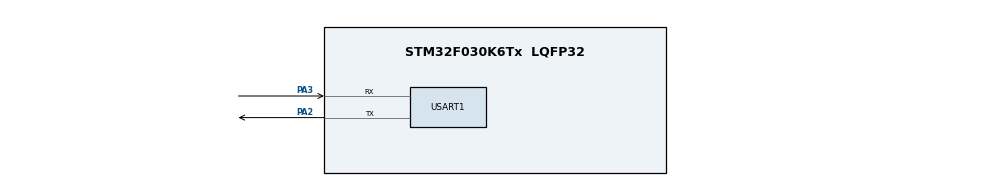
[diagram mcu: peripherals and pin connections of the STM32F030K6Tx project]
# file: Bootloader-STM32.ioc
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Mcu.Family=STM32F0
Mcu.Name=STM32F030K6Tx
Mcu.Package=LQFP32
PA2.Mode=Asynchronous
PA2.Signal=USART1_TX
PA3.Mode=Asynchronous
PA3.Signal=USART1_RX
ProjectManager.HeapSize=0x200
ProjectManager.StackSize=0x400
ProjectManager.TargetToolchain=TrueSTUDIO
USART1.VirtualMode-Asynchronous=VM_ASYNC
board=custom

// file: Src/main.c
/**
  ******************************************************************************
  * @file           : main.c
  * @brief          : Main program body
  ******************************************************************************
  ** This notice applies to any and all portions of this file
  * that are not between comment pairs USER CODE BEGIN and
  * USER CODE END. Other portions of this file, whether
  * inserted by the user or by software development tools
  * are owned by their respective copyright owners.
  *
  * COPYRIGHT(c) 2018 STMicroelectronics
  *
  * Redistribution and use in source and binary forms, with or without modification,
  * are permitted provided that the following conditions are met:
  *   1. Redistributions of source code must retain the above copyright notice,
  *      this list of conditions and the following disclaimer.
  *   2. Redistributions in binary form must reproduce the above copyright notice,
  *      this list of conditions and the following disclaimer in the documentation
  *      and/or other materials provided with the distribution.
  *   3. Neither the name of STMicroelectronics nor the names of its contributors
  *      may be used to endorse or promote products derived from this software
  *      without specific prior written permission.
  *
  * THIS SOFTWARE IS PROVIDED BY THE COPYRIGHT HOLDERS AND CONTRIBUTORS "AS IS"
  * AND ANY EXPRESS OR IMPLIED WARRANTIES, INCLUDING, BUT NOT LIMITED TO, THE
  * IMPLIED WARRANTIES OF MERCHANTABILITY AND FITNESS FOR A PARTICULAR PURPOSE ARE
  * DISCLAIMED. IN NO EVENT SHALL THE COPYRIGHT HOLDER OR CONTRIBUTORS BE LIABLE
  * FOR ANY DIRECT, INDIRECT, INCIDENTAL, SPECIAL, EXEMPLARY, OR CONSEQUENTIAL
  * DAMAGES (INCLUDING, BUT NOT LIMITED TO, PROCUREMENT OF SUBSTITUTE GOODS OR
  * SERVICES; LOSS OF USE, DATA, OR PROFITS; OR BUSINESS INTERRUPTION) HOWEVER
  * CAUSED AND ON ANY THEORY OF LIABILITY, WHETHER IN CONTRACT, STRICT LIABILITY,
  * OR TORT (INCLUDING NEGLIGENCE OR OTHERWISE) ARISING IN ANY WAY OUT OF THE USE
  * OF THIS SOFTWARE, EVEN IF ADVISED OF THE POSSIBILITY OF SUCH DAMAGE.
  *
  ******************************************************************************
  */
#include "main.h"
#include "stm32f0xx_hal.h"

/* USER CODE BEGIN Includes */

#include "boot.h"

/* USER CODE END Includes */

/* USER CODE BEGIN PV */
/* Private variables ---------------------------------------------------------*/

/* USER CODE END PV */

void SystemClock_Config(void);
static void MX_GPIO_Init(void);
static void MX_USART1_UART_Init(void);

/* USER CODE BEGIN PFP */
/* Private function prototypes -----------------------------------------------*/

/* USER CODE END PFP */

int main(void)
{

  /* MCU Configuration----------------------------------------------------------*/

  /* Reset of all peripherals, Initializes the Flash interface and the Systick. */
  HAL_Init();

  /* Configure the system clock */
  SystemClock_Config();

  /* Initialize all configured peripherals */
  MX_GPIO_Init();
  MX_USART1_UART_Init();
  /* USER CODE BEGIN 2 */

  BootInit();

  /* USER CODE END 2 */

  /* Infinite loop */
  /* USER CODE BEGIN WHILE */
  while (1)
  {
	  BootTask();

  /* USER CODE END WHILE */

  }

}

void SystemClock_Config(void)
{

  RCC_OscInitTypeDef RCC_OscInitStruct;
  RCC_ClkInitTypeDef RCC_ClkInitStruct;
  RCC_PeriphCLKInitTypeDef PeriphClkInit;

    /**Initializes the CPU, AHB and APB busses clocks
    */
  RCC_OscInitStruct.OscillatorType = RCC_OSCILLATORTYPE_HSI;
  RCC_OscInitStruct.HSIState = RCC_HSI_ON;
  RCC_OscInitStruct.HSICalibrationValue = 16;
  RCC_OscInitStruct.PLL.PLLState = RCC_PLL_NONE;
  if (HAL_RCC_OscConfig(&RCC_OscInitStruct) != HAL_OK)
  {
    _Error_Handler(__FILE__, __LINE__);
  }

    /**Initializes the CPU, AHB and APB busses clocks
    */
  RCC_ClkInitStruct.ClockType = RCC_CLOCKTYPE_HCLK|RCC_CLOCKTYPE_SYSCLK
                              |RCC_CLOCKTYPE_PCLK1;
  RCC_ClkInitStruct.SYSCLKSource = RCC_SYSCLKSOURCE_HSI;
  RCC_ClkInitStruct.AHBCLKDivider = RCC_SYSCLK_DIV1;
  RCC_ClkInitStruct.APB1CLKDivider = RCC_HCLK_DIV1;

  if (HAL_RCC_ClockConfig(&RCC_ClkInitStruct, FLASH_LATENCY_0) != HAL_OK)
  {
    _Error_Handler(__FILE__, __LINE__);
  }

  PeriphClkInit.PeriphClockSelection = RCC_PERIPHCLK_USART1;
  PeriphClkInit.Usart1ClockSelection = RCC_USART1CLKSOURCE_PCLK1;
  if (HAL_RCCEx_PeriphCLKConfig(&PeriphClkInit) != HAL_OK)
  {
    _Error_Handler(__FILE__, __LINE__);
  }

    /**Configure the Systick interrupt time
    */
  HAL_SYSTICK_Config(HAL_RCC_GetHCLKFreq()/1000);

    /**Configure the Systick
    */
  HAL_SYSTICK_CLKSourceConfig(SYSTICK_CLKSOURCE_HCLK);

  /* SysTick_IRQn interrupt configuration */
  HAL_NVIC_SetPriority(SysTick_IRQn, 0, 0);
}

/* USART1 init function */
static void MX_USART1_UART_Init(void)
{

  LL_USART_InitTypeDef USART_InitStruct;

  LL_GPIO_InitTypeDef GPIO_InitStruct;

  /* Peripheral clock enable */
  LL_APB1_GRP2_EnableClock(LL_APB1_GRP2_PERIPH_USART1);

  /**USART1 GPIO Configuration
  PA2   ------> USART1_TX
  PA3   ------> USART1_RX
  */
  GPIO_InitStruct.Pin = LL_GPIO_PIN_2;
  GPIO_InitStruct.Mode = LL_GPIO_MODE_ALTERNATE;
  GPIO_InitStruct.Speed = LL_GPIO_SPEED_FREQ_HIGH;
  GPIO_InitStruct.OutputType = LL_GPIO_OUTPUT_PUSHPULL;
  GPIO_InitStruct.Pull = LL_GPIO_PULL_NO;
  GPIO_InitStruct.Alternate = LL_GPIO_AF_1;
  LL_GPIO_Init(GPIOA, &GPIO_InitStruct);

  GPIO_InitStruct.Pin = LL_GPIO_PIN_3;
  GPIO_InitStruct.Mode = LL_GPIO_MODE_ALTERNATE;
  GPIO_InitStruct.Speed = LL_GPIO_SPEED_FREQ_HIGH;
  GPIO_InitStruct.OutputType = LL_GPIO_OUTPUT_PUSHPULL;
  GPIO_InitStruct.Pull = LL_GPIO_PULL_NO;
  GPIO_InitStruct.Alternate = LL_GPIO_AF_1;
  LL_GPIO_Init(GPIOA, &GPIO_InitStruct);

  USART_InitStruct.BaudRate = 38400;
  USART_InitStruct.DataWidth = LL_USART_DATAWIDTH_8B;
  USART_InitStruct.StopBits = LL_USART_STOPBITS_1;
  USART_InitStruct.Parity = LL_USART_PARITY_NONE;
  USART_InitStruct.TransferDirection = LL_USART_DIRECTION_TX_RX;
  USART_InitStruct.HardwareFlowControl = LL_USART_HWCONTROL_NONE;
  USART_InitStruct.OverSampling = LL_USART_OVERSAMPLING_16;
  LL_USART_Init(USART1, &USART_InitStruct);

  LL_USART_DisableIT_CTS(USART1);

  LL_USART_DisableOverrunDetect(USART1);

  LL_USART_ConfigAsyncMode(USART1);

  LL_USART_Enable(USART1);

}

/** Pinout Configuration
*/
static void MX_GPIO_Init(void)
{

  /* GPIO Ports Clock Enable */
  LL_AHB1_GRP1_EnableClock(LL_AHB1_GRP1_PERIPH_GPIOA);

}

void _Error_Handler(char *file, int line)
{
  while(1)
  {
  }
}

/************************ (C) COPYRIGHT STMicroelectronics *****END OF FILE****/
